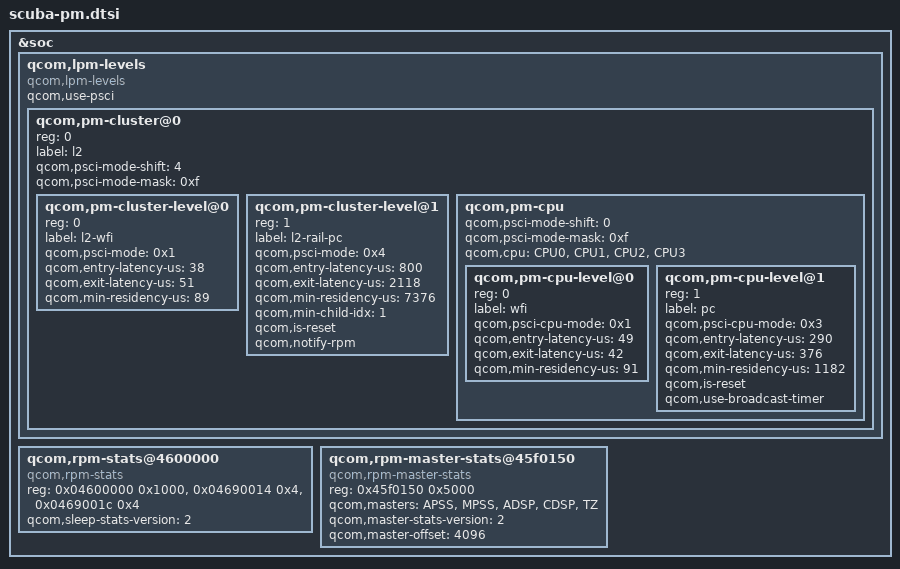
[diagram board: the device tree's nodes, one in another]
&soc {

	qcom,lpm-levels {
		compatible = "qcom,lpm-levels";
		qcom,use-psci;
		#address-cells = <1>;
		#size-cells = <0>;
		qcom,pm-cluster@0 {
			reg = <0>;
			#address-cells = <1>;
			#size-cells = <0>;
			label = "l2";
			qcom,psci-mode-shift = <4>;
			qcom,psci-mode-mask = <0xf>;

			qcom,pm-cluster-level@0 { /* D1 */
				reg = <0>;
				label = "l2-wfi";
				qcom,psci-mode = <0x1>;
				qcom,entry-latency-us = <38>;
				qcom,exit-latency-us = <51>;
				qcom,min-residency-us = <89>;
			};

			qcom,pm-cluster-level@1 { /* D4 */
				reg = <1>;
				label = "l2-rail-pc";
				qcom,psci-mode = <0x4>;
				qcom,entry-latency-us = <800>;
				qcom,exit-latency-us = <2118>;
				qcom,min-residency-us = <7376>;
				qcom,min-child-idx = <1>;
				qcom,is-reset;
				qcom,notify-rpm;
			};

			qcom,pm-cpu {
				#address-cells = <1>;
				#size-cells = <0>;
				qcom,psci-mode-shift = <0>;
				qcom,psci-mode-mask = <0xf>;
				qcom,cpu = <&CPU0 &CPU1 &CPU2 &CPU3>;

				qcom,pm-cpu-level@0 { /* C1 */
					reg = <0>;
					label = "wfi";
					qcom,psci-cpu-mode = <0x1>;
					qcom,entry-latency-us = <49>;
					qcom,exit-latency-us = <42>;
					qcom,min-residency-us = <91>;
				};

				qcom,pm-cpu-level@1 {  /* C3 */
					reg = <1>;
					label = "pc";
					qcom,psci-cpu-mode = <0x3>;
					qcom,entry-latency-us = <290>;
					qcom,exit-latency-us = <376>;
					qcom,min-residency-us = <1182>;
					qcom,is-reset;
					qcom,use-broadcast-timer;
				};
			};
		};

	};

	qcom,rpm-stats@4600000 {
		compatible = "qcom,rpm-stats";
		reg = <0x04600000 0x1000>,
		      <0x04690014 0x4>,
		      <0x0469001c 0x4>;
		reg-names = "phys_addr_base", "offset_addr",
						"heap_phys_addrbase";
		qcom,sleep-stats-version = <2>;
	};

	qcom,rpm-master-stats@45f0150 {
		compatible = "qcom,rpm-master-stats";
		reg = <0x45f0150 0x5000>;
		qcom,masters = "APSS", "MPSS", "ADSP", "CDSP", "TZ";
		qcom,master-stats-version = <2>;
		qcom,master-offset = <4096>;
	};
};
